# UPD70F3508 register map
Vendor: Renesas; Series: V850E2/Px4; File version: 1.0
CPU: other r0p0, little endian, no MPU, FPU, 4 interrupt priority bits
Registers are 8-bit, read-write, reset 0x0 unless marked. A register's access mark holds for its fields unless they carry their own. Offsets are from the block's base; [hi:lo] are bit positions; {n}, {i} and the like mark numbered series.

## FCN0 — CAN Controller (FCN) instance 0
Base 0xFF480000
Same registers: FCN1 0xFF4A0000
0x08 FCN0GMCSPRE reset 0xF — FCN0 global clock selection register
  [3:0] FCN0GMCSPRSC — Clock prescaler selection [3:0]
0x20 FCN0GMADCTL — FCN0 global automatic block transmission delay register
  [3:0] FCN0GMADSSAD — ABT delay setting [3:0]
0x248 FCN0CMLCSTR — FCN0 module last error information register
  [2:0] FCN0CMLCSSLC — Last error code [2:0]
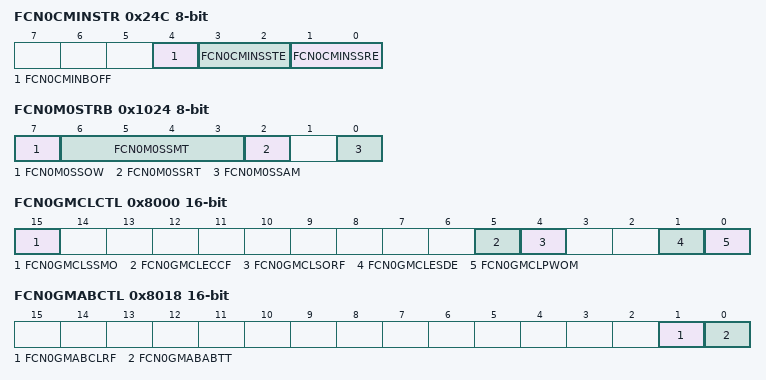
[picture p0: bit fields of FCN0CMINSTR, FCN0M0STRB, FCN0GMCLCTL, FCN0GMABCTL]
0x24C FCN0CMINSTR ro — FCN0 module information register
  [4] FCN0CMINBOFF — Bus-off status flag
  [3:2] FCN0CMINSSTE — Transmit error status [1:0] (bits [3:2])
  [1:0] FCN0CMINSSRE — Receive error status [1:0]
0x268 FCN0CMBRPRS reset 0xFF — FCN0 module bit-rate prescaler register
  [7:0] FCN0CMBRPRS — Bit-rate prescaler value [7:0]
0x278 FCN0CMLISTR ro — FCN0 module last in-pointer register (receive history list)
  [7:0] FCN0CMLISSLR — Last receive history in-pointer [7:0]
0x288 FCN0CMLOSTR ro — FCN0 module last out-pointer register (transmit history list)
  [7:0] FCN0CMLOSSLT — Last transmit history out-pointer [7:0]
0x1000 FCN0M0DAT0B — FCN0 message buffer 0 data byte 0 register (8-bit access; array step 0x40 for buffers 1-63)
  [7:0] FCN0M0SSD0 — Data byte 0 [7:0]
{0x1000+4i} FCN0M0DAT{i}B (i=1..7) — FCN0 message buffer 0 data byte {i} register (8-bit)
0x1020 FCN0M0DTLGB — FCN0 message buffer 0 data length register (8-bit)
  [3:0] FCN0M0DTLG — Data length code [3:0]
0x1024 FCN0M0STRB — FCN0 message buffer 0 configuration register (8-bit)
  [7] FCN0M0SSOW — Message buffer direction (0=RX, 1=TX) (bit 7)
  [6:3] FCN0M0SSMT — Message buffer type [3:0] (bits [6:3])
  [2] FCN0M0SSRT — Remote frame type (bit 2)
  [0] FCN0M0SSAM — Accept mask selection (bit 0)
0x8000 FCN0GMCLCTL 16-bit — FCN0 global control register (bit-set/clear mechanism; read gives status, write uses SE/CL upper/lower byte)
  [15] FCN0GMCLSSMO — Message buffer / history register access enable (read-only; set by HW)
  [5] FCN0GMCLECCF — Message buffer RAM read error detect flag
  [4] FCN0GMCLSORF — Software reset execution status
  [1] FCN0GMCLESDE — Forced shut-down enable flag
  [0] FCN0GMCLPWOM — Global operating mode (0=disabled, 1=enabled)
0x8018 FCN0GMABCTL 16-bit — FCN0 global automatic block transmission register (bit-set/clear mechanism)
  [1] FCN0GMABCLRF — ABT clear flag (read)
  [0] FCN0GMABABTT — ABT active flag (read)
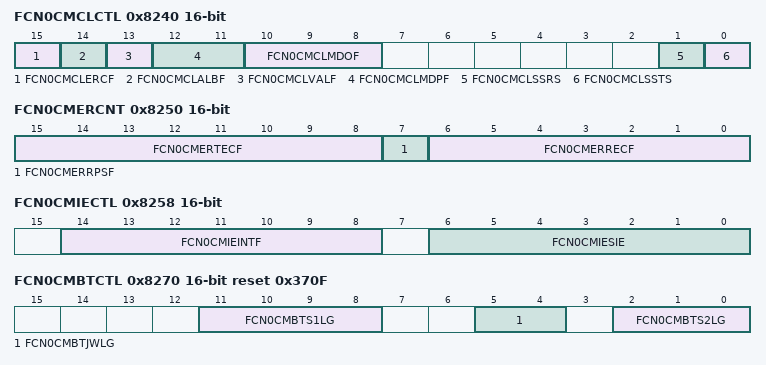
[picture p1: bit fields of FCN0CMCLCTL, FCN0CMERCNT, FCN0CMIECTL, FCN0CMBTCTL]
0x8240 FCN0CMCLCTL 16-bit — FCN0 module control register (bit-set/clear mechanism)
  [15] FCN0CMCLERCF — Error counter overflow flag (bit 15)
  [14] FCN0CMCLALBF — Arbitration lost flag (bit 14)
  [13] FCN0CMCLVALF — Valid protocol operation flag (bit 13)
  [12:11] FCN0CMCLMDPF — Module operating mode phase flags [1:0] (bits [12:11])
  [10:8] FCN0CMCLMDOF — Module operating mode flags [2:0] (bits [10:8])
  [1] FCN0CMCLSSRS — Single-shot mode status (bit 1)
  [0] FCN0CMCLSSTS — Self-test mode status (bit 0)
0x8250 FCN0CMERCNT 16-bit ro — FCN0 module error counter register
  [15:8] FCN0CMERTECF — Transmit error counter [7:0] (bits [15:8])
  [7] FCN0CMERRPSF — Receive passive error flag (bit 7)
  [6:0] FCN0CMERRECF — Receive error counter [6:0] (bits [6:0])
0x8258 FCN0CMIECTL 16-bit — FCN0 module interrupt enable register (bit-set/clear mechanism)
  [14:8] FCN0CMIEINTF — Interrupt flag bits [6:0] (read, bits [14:8])
  [6:0] FCN0CMIESIE — Status interrupt enable bits [6:0] (write, bits [6:0])
0x8260 FCN0CMISCTL 16-bit — FCN0 module interrupt status register (bit-set/clear mechanism)
  [14:8] FCN0CMISITSF — Interrupt status flag bits [6:0] (read, bits [14:8])
  [14:8] FCN0CMISCLTS — Interrupt status clear bits [6:0] (write, bits [14:8])
0x8270 FCN0CMBTCTL 16-bit reset 0x370F — FCN0 module bit-rate register
  [11:8] FCN0CMBTS1LG — Bit segment 1 length [3:0] (bits [11:8])
  [5:4] FCN0CMBTJWLG — Synchronization jump width [1:0] (bits [5:4])
  [2:0] FCN0CMBTS2LG — Bit segment 2 length [2:0] (bits [2:0])
0x8280 FCN0CMRGRX 16-bit reset 0x2 — FCN0 module receive history list register (bit-set/clear mechanism; reset xx02H, x=don't-care)
  [9] FCN0CMRGSSPM — History list write pointer overflow flag (read, bit 9)
  [8] FCN0CMRGRVFF — History list full flag (read, bit 8)
  [7:0] FCN0CMRDSSPT — History list read pointer [7:0] (read, bits [7:0])
  [0] FCN0CMRGCLRV — History list clear (write, bit 0)
0x8290 FCN0CMTGTX 16-bit reset 0x2 — FCN0 module transmit history list register (bit-set/clear mechanism; reset xx02H, x=don't-care)
  [9] FCN0CMTGSSPM — Transmit history list overflow flag (read, bit 9)
  [8] FCN0CMTGTVFF — Transmit history list full flag (read, bit 8)
  [7:0] FCN0CMTGSSPT — Transmit history list read pointer [7:0] (read, bits [7:0])
  [0] FCN0CMTGCLTV — Transmit history list clear (write, bit 0)
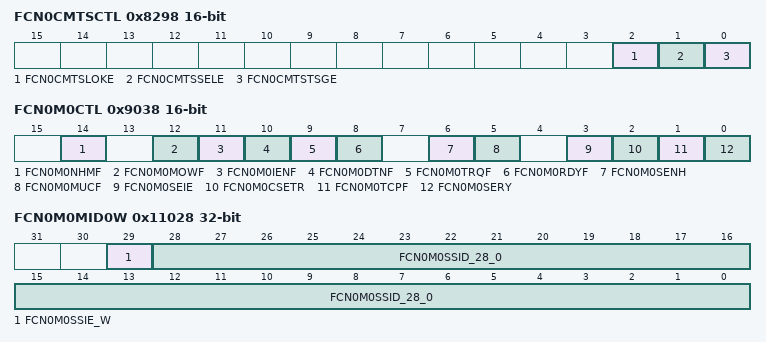
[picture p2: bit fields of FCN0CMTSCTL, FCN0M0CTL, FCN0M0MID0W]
0x8298 FCN0CMTSCTL 16-bit — FCN0 module time stamp register (bit-set/clear mechanism)
  [2] FCN0CMTSLOKE — Time stamp lock enable flag (read, bit 2)
  [1] FCN0CMTSSELE — Time stamp select enable flag (read, bit 1)
  [0] FCN0CMTSTSGE — Time stamp trigger enable flag (read, bit 0)
0x8300 FCN0CMMKCTL01H 16-bit — FCN0 module mask 1 low 16-bit register (ID bits [15:0])
  [15:0] FCN0CMMKSSID_15_0 — Mask ID bits [15:0]
0x8308 FCN0CMMKCTL02H 16-bit — FCN0 module mask 1 high 16-bit register (ID bits [28:16])
  [12:0] FCN0CMMKSSID_28_16 — Mask ID bits [28:16]
0x8310 FCN0CMMKCTL03H 16-bit — FCN0 module mask 2 low 16-bit register (ID bits [15:0])
0x8318 FCN0CMMKCTL04H 16-bit — FCN0 module mask 2 high 16-bit register (ID bits [28:16])
0x8320 FCN0CMMKCTL05H 16-bit — FCN0 module mask 3 low 16-bit register (ID bits [15:0])
0x8328 FCN0CMMKCTL06H 16-bit — FCN0 module mask 3 high 16-bit register (ID bits [28:16])
0x8330 FCN0CMMKCTL07H 16-bit — FCN0 module mask 4 low 16-bit register (ID bits [15:0])
0x8338 FCN0CMMKCTL08H 16-bit — FCN0 module mask 4 high 16-bit register (ID bits [28:16])
0x8340 FCN0CMMKCTL09H 16-bit — FCN0 module mask 5 low 16-bit register (ID bits [15:0])
0x8348 FCN0CMMKCTL10H 16-bit — FCN0 module mask 5 high 16-bit register (ID bits [28:16])
0x8350 FCN0CMMKCTL11H 16-bit — FCN0 module mask 6 low 16-bit register (ID bits [15:0])
0x8358 FCN0CMMKCTL12H 16-bit — FCN0 module mask 6 high 16-bit register (ID bits [28:16])
0x8360 FCN0CMMKCTL13H 16-bit — FCN0 module mask 7 low 16-bit register (ID bits [15:0])
0x8368 FCN0CMMKCTL14H 16-bit — FCN0 module mask 7 high 16-bit register (ID bits [28:16])
0x8370 FCN0CMMKCTL15H 16-bit — FCN0 module mask 8 low 16-bit register (ID bits [15:0])
0x8378 FCN0CMMKCTL16H 16-bit — FCN0 module mask 8 high 16-bit register (ID bits [28:16])
0x9000 FCN0M0DAT0H 16-bit — FCN0 message buffer 0 data bytes 0-1 register (16-bit alias; array step 0x40)
0x9008 FCN0M0DAT2H 16-bit — FCN0 message buffer 0 data bytes 2-3 register (16-bit alias)
0x9010 FCN0M0DAT4H 16-bit — FCN0 message buffer 0 data bytes 4-5 register (16-bit alias)
0x9018 FCN0M0DAT6H 16-bit — FCN0 message buffer 0 data bytes 6-7 register (16-bit alias)
0x9028 FCN0M0MID0H 16-bit — FCN0 message buffer 0 message ID register low word (16-bit; ID bits [15:0])
  [15:0] FCN0M0SSID_15_0 — Message ID bits [15:0]
0x9030 FCN0M0MID1H 16-bit — FCN0 message buffer 0 message ID register high word (16-bit; ID bits [28:16] + IDE bit)
  [13] FCN0M0SSIE — IDE flag — extended frame (bit 13)
  [4:0] FCN0M0SSID_28_24 — Message ID bits [28:24] (bits [4:0])
  [7:0] FCN0M0SSID_23_16 — Message ID bits [23:16] (bits [7:0] in high byte)
0x9038 FCN0M0CTL 16-bit — FCN0 message buffer 0 control register (bit-set/clear mechanism)
  [14] FCN0M0NHMF — New history message flag (read, bit 14)
  [12] FCN0M0MOWF — Message overwrite flag (read, bit 12)
  [11] FCN0M0IENF — Interrupt enable flag (read, bit 11)
  [10] FCN0M0DTNF — Data new flag (read, bit 10)
  [9] FCN0M0TRQF — Transmit request pending flag (read, bit 9)
  [8] FCN0M0RDYF — Buffer ready flag (read, bit 8)
  [6] FCN0M0SENH — Set new history flag (write-SE, bit 6)
  [5] FCN0M0MUCF — Multiple use counter flag (read, bit 5)
  [3] FCN0M0SEIE — Set interrupt enable (write-SE, bit 3)
  [2] FCN0M0CSETR — Set/cancel transmit request (write, bit 2)
  [1] FCN0M0TCPF — Transmit cancel pending flag (read, bit 1)
  [0] FCN0M0SERY — Set buffer ready (write, bit 0)
0x100C0 FCN0DNBMRX0 32-bit ro — FCN0 global data new bit monitor register 0 (buffers 0-31, one bit per buffer)
  [31:0] FCN0DNBMSSDN_31_0 — Data new flags for message buffers 31:0
0x100D0 FCN0DNBMRX1 32-bit ro — FCN0 global data new bit monitor register 1 (buffers 32-63, one bit per buffer)
  [31:0] FCN0DNBMSSDN_63_32 — Data new flags for message buffers 63:32
0x10300 FCN0CMMKCTL01W 32-bit — FCN0 module mask 1 32-bit register (full ID bits [28:0])
  [28:0] FCN0CMMKSSID_28_0 — Mask ID bits [28:0]
0x10310 FCN0CMMKCTL03W 32-bit — FCN0 module mask 2 32-bit register (full ID bits [28:0])
0x10320 FCN0CMMKCTL05W 32-bit — FCN0 module mask 3 32-bit register (full ID bits [28:0])
0x10330 FCN0CMMKCTL07W 32-bit — FCN0 module mask 4 32-bit register (full ID bits [28:0])
0x10340 FCN0CMMKCTL09W 32-bit — FCN0 module mask 5 32-bit register (full ID bits [28:0])
0x10350 FCN0CMMKCTL11W 32-bit — FCN0 module mask 6 32-bit register (full ID bits [28:0])
0x10360 FCN0CMMKCTL13W 32-bit — FCN0 module mask 7 32-bit register (full ID bits [28:0])
0x10370 FCN0CMMKCTL15W 32-bit — FCN0 module mask 8 32-bit register (full ID bits [28:0])
0x11000 FCN0M0DAT0W 32-bit — FCN0 message buffer 0 data bytes 0-3 register (32-bit alias)
0x11010 FCN0M0DAT4W 32-bit — FCN0 message buffer 0 data bytes 4-7 register (32-bit alias)
0x11028 FCN0M0MID0W 32-bit — FCN0 message buffer 0 message ID register 32-bit alias (ID [28:0] + IDE bit)
  [29] FCN0M0SSIE_W — IDE flag — extended frame (bit 29)
  [28:0] FCN0M0SSID_28_0 — Message ID bits [28:0]
